# ABE_CM1 register map
Vendor: Texas Instruments
Peripheral module from a debugger description file (folder omap4430).
Registers are 32-bit, access per field, reset 0x30000 unless marked. A register's access mark holds for its fields unless they carry their own. Offsets are as the file gives them; lines under a group give offsets from that group; [hi:lo] are bit positions; {n}, {i} and the like mark numbered series; 'fields as' and 'values as' point back to an identical list; <NAME> marks a mode.

## ABE_CM1
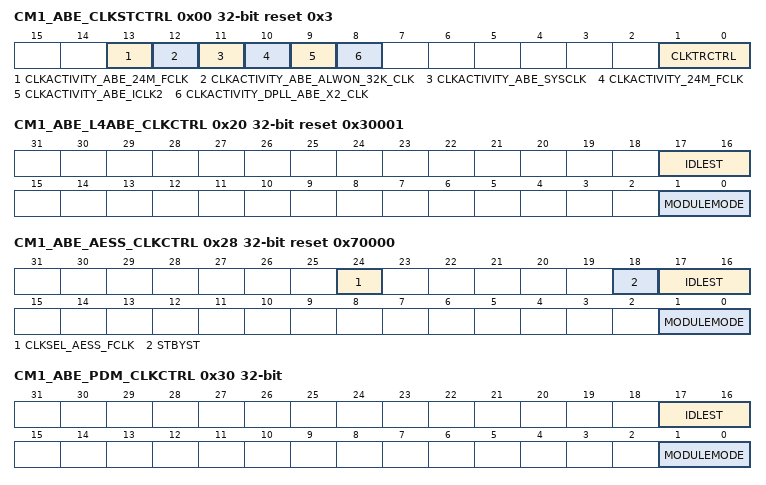
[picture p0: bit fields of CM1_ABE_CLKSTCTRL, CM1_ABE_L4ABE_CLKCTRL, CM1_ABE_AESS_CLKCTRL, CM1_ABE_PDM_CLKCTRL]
0x00 CM1_ABE_CLKSTCTRL reset 0x3 — This register enables the ABE domain power state transition. It controls the hardware supervised domain power state transition between ON-ACTIVE and ON-INACTIVE states. It also holds 1 status bit per clock input of the domain.
  [13] CLKACTIVITY_ABE_24M_FCLK ro — This field indicates the state of the ABE_24M_FCLK clock in the domain. [warm reset insensitive]
    0=CLKACTIVITY_ABE_24M_FCLK_0_r (Corresponding clock is definitely gated); 1=CLKACTIVITY_ABE_24M_FCLK_1_r (Corresponding clock is running or gating/ungating transition is ongoing)
  [12] CLKACTIVITY_ABE_ALWON_32K_CLK ro — This field indicates the state of the ABE_ALWON_32K_CLK clock in the domain. [warm reset insensitive]
    0=CLKACTIVITY_ABE_ALWON_32K_CLK_0_r (Corresponding clock is definitely gated); 1=CLKACTIVITY_ABE_ALWON_32K_CLK_1_r (Corresponding clock is running or gating/ungating transition is ongoing)
  [11] CLKACTIVITY_ABE_SYSCLK ro — This field indicates the state of the ABE_SYSCLK clock in the domain. [warm reset insensitive]
    0=CLKACTIVITY_ABE_SYSCLK_0_r (Corresponding clock is definitely gated); 1=CLKACTIVITY_ABE_SYSCLK_1_r (Corresponding clock is running or gating/ungating transition is ongoing)
  [10] CLKACTIVITY_24M_FCLK ro — This field indicates the state of the 24M_FCLK clock in the domain. [warm reset insensitive]
    0=CLKACTIVITY_24M_FCLK_0_r (Corresponding clock is definitely gated); 1=CLKACTIVITY_24M_FCLK_1_r (Corresponding clock is running or gating/ungating transition is ongoing)
  [9] CLKACTIVITY_ABE_ICLK2 ro — This field indicates the state of the ABE_ICLK2 interface clock in the domain. [warm reset insensitive]
    0=CLKACTIVITY_ABE_ICLK2_0_r (Corresponding clock is definitely gated); 1=CLKACTIVITY_ABE_ICLK2_1_r (Corresponding clock is running or gating/ungating transition is ongoing)
  [8] CLKACTIVITY_DPLL_ABE_X2_CLK ro — This field indicates the state of the DPLL_ABE_X2_CLK clock in the domain. [warm reset insensitive]
    0=CLKACTIVITY_DPLL_ABE_X2_CLK_0_r (Corresponding clock is definitely gated); 1=CLKACTIVITY_DPLL_ABE_X2_CLK_1_r (Corresponding clock is running or gating/ungating transition is ongoing)
  [1:0] CLKTRCTRL rw — Controls the clock state transition of the ABE clock domain.
    0=NO_SLEEP: Sleep transition cannot be initiated. Wakeup transition may however occur.; 1=SW_SLEEP: Start a software forced sleep transition on the domain; 2=SW_WKUP: Start a software forced wake-up transition on the domain; 3=HW_AUTO: Automatic transition is enabled. Sleep and wakeup transition are based upon hardware conditions.
0x20 CM1_ABE_L4ABE_CLKCTRL access not given reset 0x30001 — This register manages the L4ABE clocks.
  [17:16] IDLEST ro — Module idle status. [warm reset insensitive]
    0=IDLEST_0_r (Module is fully functional, including INTRCONN); 1=IDLEST_1_r (Module is performing transition: wakeup, or sleep, or sleep abortion); 2=IDLEST_2_r (Module is in Idle mode (only INTRCONN part). It is functional if using separate functional clock); 3=IDLEST_3_r (Module is disabled and cannot be accessed)
  [1:0] MODULEMODE — Control the way mandatory clocks are managed. (access R Rreturns)
    1=MODULEMODE_1_r (Module is managed automatically by hardware according to clock domain transition. A clock domain sleep transition put module into idle. A wakeup domain transition put it back into function. If CLKTRCTRL=3, any INTRCONN access to module is always granted. Module clocks may be gated according to the clock domain state.)
0x28 CM1_ABE_AESS_CLKCTRL reset 0x70000 — This register manages the AESS clocks.
  [24] CLKSEL_AESS_FCLK rw — Selects the ratio of AESS_FCLK to ABE_CLK
    0=AESS_FCLK is divide by 1 of ABE_CLK; 1=AESS_FCLK is divide by 2 of ABE_CLK
  [18] STBYST ro — Module standby status. [warm reset insensitive]
    0=STBYST_0_r (Module is functional (not in standby)); 1=STBYST_1_r (Module is in standby)
  [17:16] IDLEST ro — Module idle status. [warm reset insensitive]
    values as CM1_ABE_L4ABE_CLKCTRL.IDLEST
  [1:0] MODULEMODE rw — Control the way mandatory clocks are managed.
    0=Module is disable by software. Any INTRCONN access to module results in an error, except if resulting from a module wakeup (asynchronous wakeup).; 1=MODULEMODE_1_r (Reserved); 2=Module is explicitly enabled. Interface clock (if not used for functions) may be gated according to the clock domain state. Functional clocks are guarantied to stay present. As long as in this configuration, power domain sleep transition cannot happen.; 3=MODULEMODE_3_r (Reserved)
0x30 CM1_ABE_PDM_CLKCTRL — This register manages the PDM clocks.
  [17:16] IDLEST ro — Module idle status. [warm reset insensitive]
    values as CM1_ABE_L4ABE_CLKCTRL.IDLEST
  [1:0] MODULEMODE rw — Control the way mandatory clocks are managed.
    values as CM1_ABE_AESS_CLKCTRL.MODULEMODE
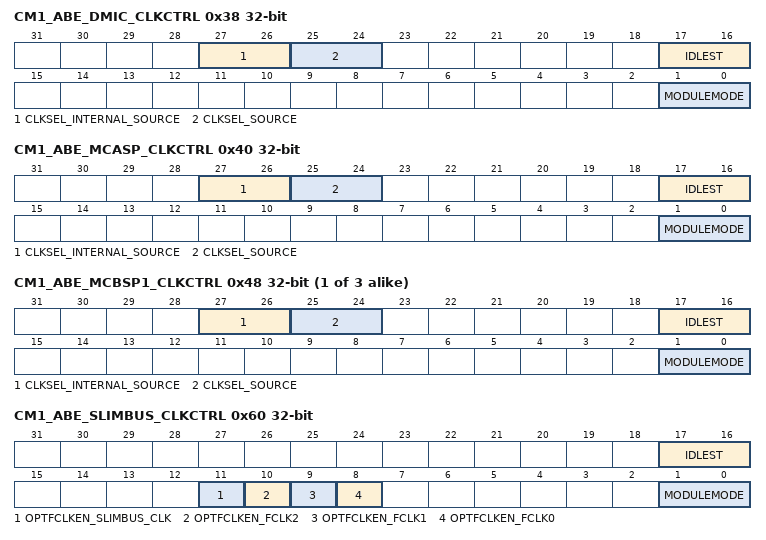
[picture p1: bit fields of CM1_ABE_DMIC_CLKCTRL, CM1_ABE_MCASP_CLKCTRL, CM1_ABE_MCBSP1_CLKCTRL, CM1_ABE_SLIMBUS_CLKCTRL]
0x38 CM1_ABE_DMIC_CLKCTRL — This register manages the DMIC clocks.
  [27:26] CLKSEL_INTERNAL_SOURCE rw — Selects the internal clock to be used as the functional clock in case CLKSEL_SOURCE selects the internal clock source as the functional clock source.
    0=24MHz clock derived from DPLL_ABE is selected; 1=ABE_SYSCLK is selected; 2=24MHz clock derived from DPLL_PER is selected
  [25:24] CLKSEL_SOURCE rw — Selects the source of the functional clock between, internal source, CLKS pad and Audio SLIMBUS_CLK pad. The switching between the clocks is not guaranteed to be glitchless.
    0=Functional clock is sourced from an internal clock; 1=Functional clock is sourced from CLKS pad; 2=Functional clock is sourced from Audio SIMBUS pad
  [17:16] IDLEST ro — Module idle status. [warm reset insensitive]
    values as CM1_ABE_L4ABE_CLKCTRL.IDLEST
  [1:0] MODULEMODE rw — Control the way mandatory clocks are managed.
    values as CM1_ABE_AESS_CLKCTRL.MODULEMODE
0x40 CM1_ABE_MCASP_CLKCTRL — This register manages the MCASP clocks.
  fields as CM1_ABE_DMIC_CLKCTRL
{0x40+8i} CM1_ABE_MCBSP{i}_CLKCTRL (i=1..3) — This register manages the MCBSP{i} clocks.
  fields as CM1_ABE_DMIC_CLKCTRL
0x60 CM1_ABE_SLIMBUS_CLKCTRL — This register manages the SLIMBUS clocks.
  [17:16] IDLEST ro — Module idle status. [warm reset insensitive]
    values as CM1_ABE_L4ABE_CLKCTRL.IDLEST
  [11] OPTFCLKEN_SLIMBUS_CLK rw — Optional functional clock control.
    0=Optional functional clock is disabled; 1=Optional functional clock is enabled
  [10] OPTFCLKEN_FCLK2 rw — Optional functional clock control.
    values as OPTFCLKEN_SLIMBUS_CLK
  [9] OPTFCLKEN_FCLK1 rw — Optional functional clock control.
    values as OPTFCLKEN_SLIMBUS_CLK
  [8] OPTFCLKEN_FCLK0 rw — Optional functional clock control.
    values as OPTFCLKEN_SLIMBUS_CLK
  [1:0] MODULEMODE rw — Control the way mandatory clocks are managed.
    values as CM1_ABE_AESS_CLKCTRL.MODULEMODE
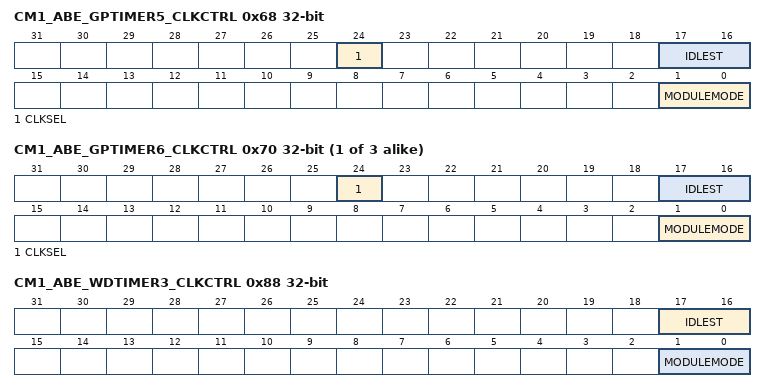
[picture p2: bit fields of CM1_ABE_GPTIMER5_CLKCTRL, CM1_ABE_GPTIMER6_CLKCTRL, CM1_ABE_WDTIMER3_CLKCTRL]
0x68 CM1_ABE_GPTIMER5_CLKCTRL — This register manages the TIMER5 clocks.
  [24] CLKSEL rw — Selects between ABE_SYSCLK and ABE_ALWON_32K_CLK as the timer functional clock
    0=Selects ABE_SYSCLK as the functional clock; 1=Selects ABE_ALWON_32K_CLK as the functional clock
  [17:16] IDLEST ro — Module idle status
    values as CM1_ABE_L4ABE_CLKCTRL.IDLEST
  [1:0] MODULEMODE rw — Control the way mandatory clocks are managed.
    values as CM1_ABE_AESS_CLKCTRL.MODULEMODE
{0x40+8i} CM1_ABE_GPTIMER{i}_CLKCTRL (i=6..8) — This register manages the TIMER{i} clocks.
  [24] CLKSEL rw — Selects between ABE_SYSCLK and ABE_ALWON_32K_CLK as the timer functional clock
    values as CM1_ABE_GPTIMER5_CLKCTRL.CLKSEL
  [17:16] IDLEST ro — Module idle status. [warm reset insensitive]
    values as CM1_ABE_L4ABE_CLKCTRL.IDLEST
  [1:0] MODULEMODE rw — Control the way mandatory clocks are managed.
    values as CM1_ABE_AESS_CLKCTRL.MODULEMODE
0x88 CM1_ABE_WDTIMER3_CLKCTRL — This register manages the WDT3 clocks.
  fields as CM1_ABE_PDM_CLKCTRL
